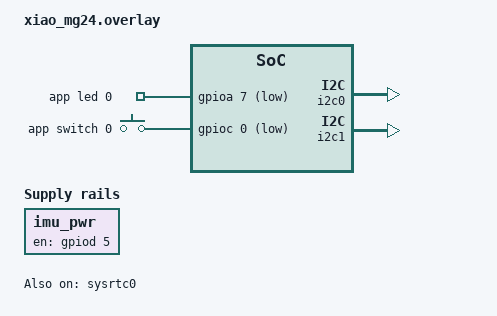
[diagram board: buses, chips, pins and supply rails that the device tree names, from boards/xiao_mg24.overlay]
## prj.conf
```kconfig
#configure i2c port
CONFIG_I2C=y
CONFIG_PRINTK=y
CONFIG_REGULATOR=y
CONFIG_REGULATOR_FIXED=y
CONFIG_REGULATOR_FIXED_INIT_PRIORITY=45
```

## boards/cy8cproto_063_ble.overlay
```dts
/ {
    gpiocustom {
        compatible = "gpio-keys";
        appled0: appled_0 {
            gpios = <&gpio_prt6 3 GPIO_ACTIVE_LOW>;
            label = "app led 0";
        };
    };

    aliases {
        appled0 = &appled0;
        appi2c0 = &i2c0;
        appi2c1 = &i2c1;
    };
};

i2c0: &scb6 {
	compatible = "infineon,cat1-i2c";
	status = "okay";
    pinctrl-0 = <&p6_5_scb6_i2c_sda &p6_4_scb6_i2c_scl>;
	pinctrl-names = "default";
};

i2c1: &scb1 {
	compatible = "infineon,cat1-i2c";
	status = "okay";
	pinctrl-0 = <&p10_1_scb1_i2c_sda &p10_0_scb1_i2c_scl>;
	pinctrl-names = "default";
};
```

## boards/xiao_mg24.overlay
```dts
/ {
    imu_pwr: imu-pwr {
		compatible = "regulator-fixed";
		regulator-name = "imu-pwr";
		enable-gpios = <&gpiod 5 GPIO_ACTIVE_HIGH>;
		regulator-boot-on;
        regulator-always-on;
		startup-delay-us = <5000>;
	};

    gpiocustom {
        compatible = "gpio-keys";
        appled0: appled_0 {
            gpios = <&gpioa 7 GPIO_ACTIVE_LOW>;
            label = "app led 0";
        };

        appsw_0: appsw_0 {
            gpios = <&gpioc 0 (GPIO_PULL_UP | GPIO_ACTIVE_LOW)>;
            label = "app switch 0";
        };
    };

    aliases {
        appled0 = &appled0;
        appsw0 = &appsw_0;
        apptimer0 = &sysrtc0;
        appi2c0 = &i2c0;
        appi2c1 = &i2c1;
    };
};

&sysrtc0 {
    status = "okay";
};

/* Enable and configure I2C0 */
&i2c0 {
    status = "okay";
    pinctrl-0 = <&i2c0_default>;
    pinctrl-names = "default";
};

/* Enable and configure I2C1 */
&i2c1 {
    status = "okay";
    pinctrl-0 = <&i2c1_default>;
    pinctrl-names = "default";
};

&pinctrl {
	i2c0_default: i2c0_default {
		group0 {
			pins = <I2C0_SDA_PB2>, <I2C0_SCL_PB3>;
			drive-open-drain;
			bias-pull-up;
		};
	};

	i2c1_default: i2c1_default {
		group0 {
			pins = <I2C1_SDA_PC5>, <I2C1_SCL_PC4>;
			drive-open-drain;
			bias-pull-up;
		};
	};
};
```

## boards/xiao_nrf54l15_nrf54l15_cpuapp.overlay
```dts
&timer20{
    compatible = "nordic,nrf-timer";
    status = "okay";
};

&i2c22 {
	status = "okay";
};

&i2c30 {
    status = "okay";
};

/ {
    gpiocustom {
        compatible = "gpio-keys";
        appled0: appled_0 {
            gpios = <&gpio2 0 GPIO_ACTIVE_LOW>;
            label = "app led 0";
        };

        appsw_0: appsw_0 {
            gpios = <&gpio0 0 (GPIO_PULL_UP | GPIO_ACTIVE_LOW)>;
            label = "app switch 0";
        };
    };

    aliases {
        appled0 = &appled0;
        appsw0 = &appsw_0;
        apptimer0 = &timer20;
        appi2c0 = &i2c30;
        appi2c1 = &i2c22;
    };
};
```

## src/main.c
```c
/* include files */
#include <zephyr/kernel.h>
#include <zephyr/device.h>
#include <zephyr/drivers/i2c.h>
#include <zephyr/sys/printk.h>

#define MAX_I2C_ADDRESS 127

struct device *dev_appi2c0;
struct device *dev_appi2c1;

#define I2C_0_NODE  DT_ALIAS(appi2c0)
#define I2C_1_NODE  DT_ALIAS(appi2c1)
	
void scan_i2c_devices(const struct device *dev);

int main(void)
{
    k_sleep(K_MSEC(1000));

    dev_appi2c0 = DEVICE_DT_GET(I2C_0_NODE);

    if (!dev_appi2c0)
    {
        printk("I2C_0 device not found\n");
        return -1;
    }
    else
    {
        printk("I2C_0 device found\n");
    }

	dev_appi2c1 = DEVICE_DT_GET(I2C_1_NODE);

    if (!dev_appi2c1)
    {
        printk("I2C_1 device not found\n");
        return -1;
    }
    else
    {
        printk("I2C_1 device found\n");
    }

    while(true)
    {
        scan_i2c_devices(dev_appi2c0);
		scan_i2c_devices(dev_appi2c1);
        k_sleep(K_MSEC(5000));
    }
    
    return 0;
}

void scan_i2c_devices(const struct device *dev)
{
    uint8_t data;
	uint8_t i2c_addr;
	uint8_t status;
	uint8_t number_of_bytes;

	struct i2c_msg i2cmsg;

	i2cmsg.buf = &data;
	i2cmsg.len = 1;
	i2cmsg.flags = I2C_MSG_WRITE | I2C_MSG_STOP;

	number_of_bytes = 1;

	printk("started scanning i2c devices port %s\n\n", dev->name);
	printk("    00 01 02 03 04 05 06 07 08 09 0A 0B 0C 0D 0E 0F\n00:    ");
	for(i2c_addr=1; i2c_addr<= MAX_I2C_ADDRESS; i2c_addr++)
	{
		if((i2c_addr % 0x10) == 0)	
		{
			printk("\n%2x: ",i2c_addr);
		}

		status = i2c_transfer(dev, &i2cmsg, number_of_bytes, i2c_addr);

		if(status == 0)
		{
			printk("%2x ",i2c_addr);
		}
		else
		{
			printk("-- ");
		}

		k_sleep(K_MSEC(100));	
	}
	printk("\n");
}
```
